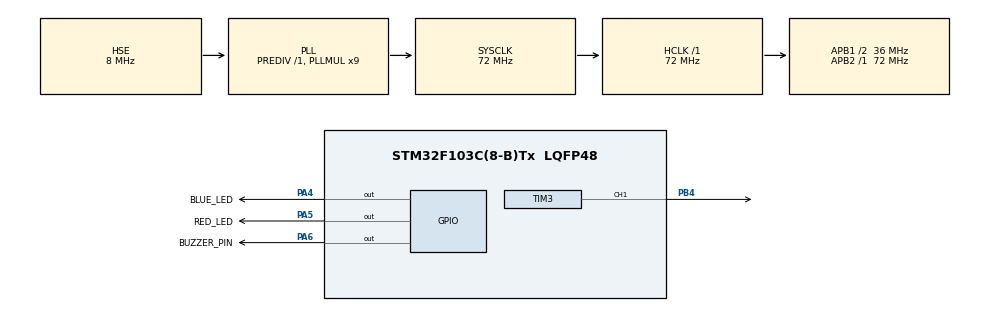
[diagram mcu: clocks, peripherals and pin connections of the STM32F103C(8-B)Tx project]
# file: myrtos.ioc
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FREERTOS.INCLUDE_xTaskGetCurrentTaskHandle=1
FREERTOS.Tasks01=MydefaultTask,24,128,StartDefaultTask,As weak,NULL,Dynamic,NULL,NULL
Mcu.Family=STM32F1
Mcu.Name=STM32F103C(8-B)Tx
Mcu.Package=LQFP48
NVIC.PriorityGroup=NVIC_PRIORITYGROUP_4
NVIC.TIM2_IRQn=true\:0\:0\:true\:false\:true\:false\:false\:true\:true
NVIC.TimeBase=TIM2_IRQn
NVIC.TimeBaseIP=TIM2
PA13.Mode=Serial_Wire
PA13.Signal=SYS_JTMS-SWDIO
PA14.Mode=Serial_Wire
PA14.Signal=SYS_JTCK-SWCLK
PA4.GPIO_Label=BLUE_LED
PA4.Signal=GPIO_Output
PA5.GPIO_Label=RED_LED
PA5.Signal=GPIO_Output
PA6.GPIO_Label=BUZZER_PIN
PA6.Signal=GPIO_Output
PB4.Signal=S_TIM3_CH1
PD0-OSC_IN.Mode=HSE-External-Oscillator
PD0-OSC_IN.Signal=RCC_OSC_IN
PD1-OSC_OUT.Mode=HSE-External-Oscillator
PD1-OSC_OUT.Signal=RCC_OSC_OUT
ProjectManager.HeapSize=0x200
ProjectManager.StackSize=0x400
ProjectManager.TargetToolchain=CMake
RCC.AHBFreq_Value=72000000
RCC.APB1CLKDivider=RCC_HCLK_DIV2
RCC.APB1Freq_Value=36000000
RCC.APB1TimFreq_Value=72000000
RCC.APB2Freq_Value=72000000
RCC.APB2TimFreq_Value=72000000
RCC.EnbaleCSS=true
RCC.HCLKFreq_Value=72000000
RCC.PLLMUL=RCC_PLL_MUL9
RCC.PLLSourceVirtual=RCC_PLLSOURCE_HSE
RCC.SYSCLKFreq_VALUE=72000000
RCC.SYSCLKSource=RCC_SYSCLKSOURCE_PLLCLK
RCC.USBFreq_Value=72000000
SH.S_TIM3_CH1.0=TIM3_CH1,PWM Generation1 CH1
TIM3.Channel-PWM\ Generation1\ CH1=TIM_CHANNEL_1
VP_FREERTOS_VS_CMSIS_V2.Mode=CMSIS_V2
VP_SYS_VS_tim2.Mode=TIM2
board=custom

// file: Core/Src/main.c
/* USER CODE BEGIN Header */
/**
  ******************************************************************************
  * @file           : main.c
  * @brief          : Main program body
  ******************************************************************************
  * @attention
  *
  * Copyright (c) 2025 STMicroelectronics.
  * All rights reserved.
  *
  * This software is licensed under terms that can be found in the LICENSE file
  * in the root directory of this software component.
  * If no LICENSE file comes with this software, it is provided AS-IS.
  *
  ******************************************************************************
  */
/* USER CODE END Header */
#include "main.h"
#include "cmsis_os.h"
#include "tim.h"
#include "gpio.h"

/* USER CODE BEGIN PM */
void vApplicationStackOverflowHook(TaskHandle_t xTask, char *pcTaskName) {

  while (1) {}
}
/* USER CODE END PM */

void SystemClock_Config(void);
void MX_FREERTOS_Init(void);

int main(void)
{

  /* MCU Configuration--------------------------------------------------------*/

  /* Reset of all peripherals, Initializes the Flash interface and the Systick. */
  HAL_Init();

  /* Configure the system clock */
  SystemClock_Config();

  /* Initialize all configured peripherals */
  MX_GPIO_Init();
  MX_TIM3_Init();

  /* Init scheduler */
  osKernelInitialize();

  /* Call init function for freertos objects (in cmsis_os2.c) */
  MX_FREERTOS_Init();

  /* Start scheduler */
  osKernelStart();

  /* We should never get here as control is now taken by the scheduler */

  /* Infinite loop */
  while (1)
  {

  }
}

void SystemClock_Config(void)
{
  RCC_OscInitTypeDef RCC_OscInitStruct = {0};
  RCC_ClkInitTypeDef RCC_ClkInitStruct = {0};

  /** Initializes the RCC Oscillators according to the specified parameters
  * in the RCC_OscInitTypeDef structure.
  */
  RCC_OscInitStruct.OscillatorType = RCC_OSCILLATORTYPE_HSE;
  RCC_OscInitStruct.HSEState = RCC_HSE_ON;
  RCC_OscInitStruct.HSEPredivValue = RCC_HSE_PREDIV_DIV1;
  RCC_OscInitStruct.HSIState = RCC_HSI_ON;
  RCC_OscInitStruct.PLL.PLLState = RCC_PLL_ON;
  RCC_OscInitStruct.PLL.PLLSource = RCC_PLLSOURCE_HSE;
  RCC_OscInitStruct.PLL.PLLMUL = RCC_PLL_MUL9;
  if (HAL_RCC_OscConfig(&RCC_OscInitStruct) != HAL_OK)
  {
    Error_Handler();
  }

  /** Initializes the CPU, AHB and APB buses clocks
  */
  RCC_ClkInitStruct.ClockType = RCC_CLOCKTYPE_HCLK|RCC_CLOCKTYPE_SYSCLK
                              |RCC_CLOCKTYPE_PCLK1|RCC_CLOCKTYPE_PCLK2;
  RCC_ClkInitStruct.SYSCLKSource = RCC_SYSCLKSOURCE_PLLCLK;
  RCC_ClkInitStruct.AHBCLKDivider = RCC_SYSCLK_DIV1;
  RCC_ClkInitStruct.APB1CLKDivider = RCC_HCLK_DIV2;
  RCC_ClkInitStruct.APB2CLKDivider = RCC_HCLK_DIV1;

  if (HAL_RCC_ClockConfig(&RCC_ClkInitStruct, FLASH_LATENCY_2) != HAL_OK)
  {
    Error_Handler();
  }

  /** Enables the Clock Security System
  */
  HAL_RCC_EnableCSS();
}

void HAL_TIM_PeriodElapsedCallback(TIM_HandleTypeDef *htim)
{
  if (htim->Instance == TIM2) {
    HAL_IncTick();
  }
}

void Error_Handler(void)
{
  __disable_irq();
  while (1)
  {
  }
}
